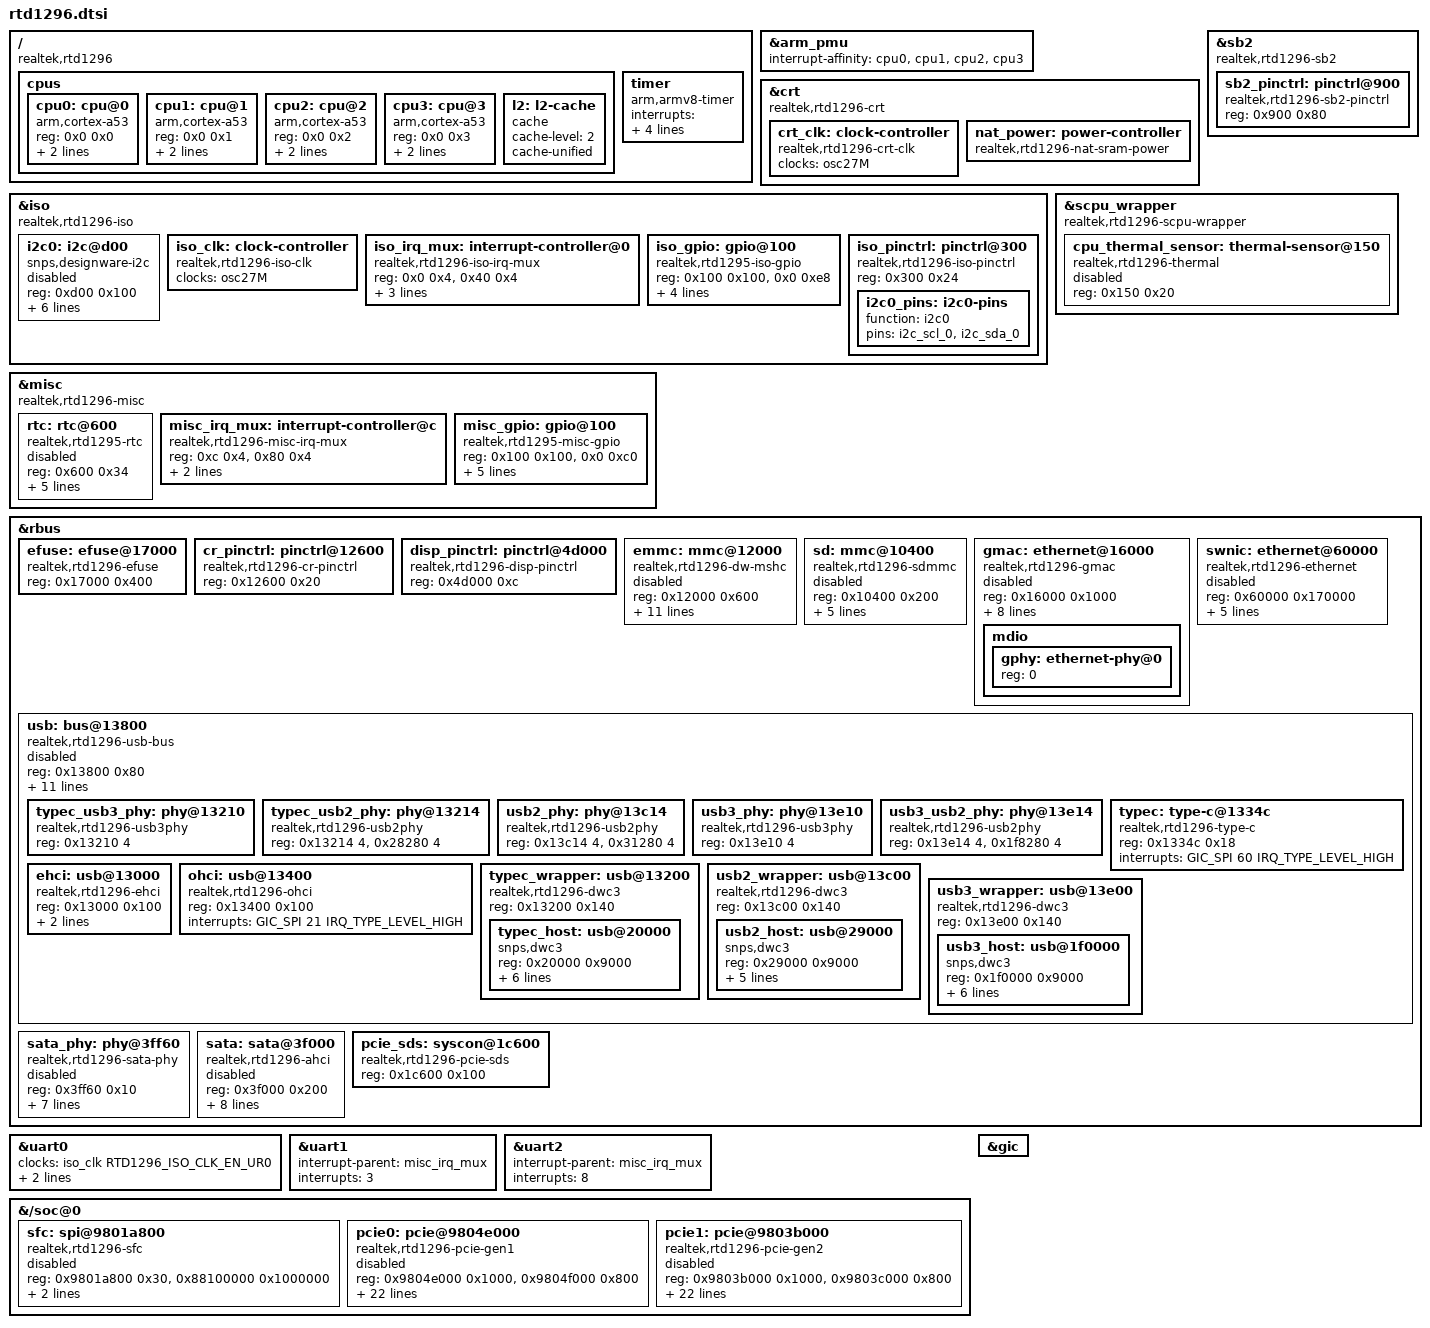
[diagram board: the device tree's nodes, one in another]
// SPDX-License-Identifier: (GPL-2.0-or-later OR BSD-2-Clause)
/*
 * Realtek RTD1296 SoC
 *
 * Copyright (c) 2017-2019 Andreas Färber
 */

#include <dt-bindings/clock/realtek,rtd1296-clk.h>

#include "rtd129x.dtsi"

/ {
	compatible = "realtek,rtd1296";

	cpus {
		#address-cells = <2>;
		#size-cells = <0>;

		cpu0: cpu@0 {
			device_type = "cpu";
			compatible = "arm,cortex-a53";
			reg = <0x0 0x0>;
			next-level-cache = <&l2>;
			clocks = <&crt_clk RTD1296_CRT_CLK_SCPU>;
			#cooling-cells = <2>;
		};

		cpu1: cpu@1 {
			device_type = "cpu";
			compatible = "arm,cortex-a53";
			reg = <0x0 0x1>;
			next-level-cache = <&l2>;
			clocks = <&crt_clk RTD1296_CRT_CLK_SCPU>;
			#cooling-cells = <2>;
		};

		cpu2: cpu@2 {
			device_type = "cpu";
			compatible = "arm,cortex-a53";
			reg = <0x0 0x2>;
			next-level-cache = <&l2>;
			clocks = <&crt_clk RTD1296_CRT_CLK_SCPU>;
			#cooling-cells = <2>;
		};

		cpu3: cpu@3 {
			device_type = "cpu";
			compatible = "arm,cortex-a53";
			reg = <0x0 0x3>;
			next-level-cache = <&l2>;
			clocks = <&crt_clk RTD1296_CRT_CLK_SCPU>;
			#cooling-cells = <2>;
		};

		l2: l2-cache {
			compatible = "cache";
			cache-level = <2>;
			cache-unified;
		};
	};

	timer {
		compatible = "arm,armv8-timer";
		interrupts = <GIC_PPI 13
			(GIC_CPU_MASK_SIMPLE(4) | IRQ_TYPE_LEVEL_LOW)>,
			     <GIC_PPI 14
			(GIC_CPU_MASK_SIMPLE(4) | IRQ_TYPE_LEVEL_LOW)>,
			     <GIC_PPI 11
			(GIC_CPU_MASK_SIMPLE(4) | IRQ_TYPE_LEVEL_LOW)>,
			     <GIC_PPI 10
			(GIC_CPU_MASK_SIMPLE(4) | IRQ_TYPE_LEVEL_LOW)>;
	};
};

&arm_pmu {
	interrupt-affinity = <&cpu0>, <&cpu1>, <&cpu2>, <&cpu3>;
};

&crt {
	compatible = "realtek,rtd1296-crt", "syscon", "simple-mfd";

	crt_clk: clock-controller {
		compatible = "realtek,rtd1296-crt-clk";
		clocks = <&osc27M>;
		#clock-cells = <1>;
	};

	nat_power: power-controller {
		compatible = "realtek,rtd1296-nat-sram-power";
		#power-domain-cells = <0>;
	};
};

&iso {
	compatible = "realtek,rtd1296-iso", "syscon", "simple-mfd";

	i2c0: i2c@d00 {
		compatible = "snps,designware-i2c";
		reg = <0xd00 0x100>;
		interrupt-parent = <&iso_irq_mux>;
		interrupts = <8>;
		clocks = <&iso_clk RTD1296_ISO_CLK_EN_I2C0>;
		resets = <&iso_reset RTD1295_ISO_RSTN_I2C_0>;
		clock-frequency = <100000>;
		#address-cells = <1>;
		#size-cells = <0>;
		pinctrl-names = "default";
		pinctrl-0 = <&i2c0_pins>;
		status = "disabled";
	};

	iso_clk: clock-controller {
		compatible = "realtek,rtd1296-iso-clk";
		clocks = <&osc27M>;
		#clock-cells = <1>;
	};

	iso_irq_mux: interrupt-controller@0 {
		compatible = "realtek,rtd1296-iso-irq-mux";
		reg = <0x0 0x4>, <0x40 0x4>;
		interrupts = <GIC_SPI 41 IRQ_TYPE_LEVEL_HIGH>,
			     <GIC_SPI 39 IRQ_TYPE_LEVEL_HIGH>;
		interrupt-names = "peripherals", "rtc-alarm";
		interrupt-controller;
		#interrupt-cells = <1>;
	};

	iso_gpio: gpio@100 {
		compatible = "realtek,rtd1295-iso-gpio";
		reg = <0x100 0x100>,
		      <0x0 0xe8>;
		interrupt-parent = <&iso_irq_mux>;
		interrupts = <19>, <20>;
		gpio-ranges = <&iso_pinctrl 0 0 35>;
		gpio-controller;
		#gpio-cells = <2>;
	};

	iso_pinctrl: pinctrl@300 {
		compatible = "realtek,rtd1296-iso-pinctrl";
		reg = <0x300 0x24>;

		i2c0_pins: i2c0-pins {
			function = "i2c0";
			pins = "i2c_scl_0", "i2c_sda_0";
		};
	};
};

&misc {
	compatible = "realtek,rtd1296-misc", "syscon", "simple-mfd";

	rtc: rtc@600 {
		compatible = "realtek,rtd1295-rtc";
		reg = <0x600 0x34>;
		clocks = <&crt_clk RTD1296_CRT_CLK_EN_RTC>;
		interrupt-parent = <&iso_irq_mux>;
		interrupts = <13>;
		realtek,iso-syscon = <&iso>;
		wakeup-source;
		status = "disabled";
	};

	misc_irq_mux: interrupt-controller@c {
		compatible = "realtek,rtd1296-misc-irq-mux";
		reg = <0xc 0x4>, <0x80 0x4>;
		interrupts = <GIC_SPI 40 IRQ_TYPE_LEVEL_HIGH>;
		interrupt-controller;
		#interrupt-cells = <1>;
	};

	misc_gpio: gpio@100 {
		compatible = "realtek,rtd1295-misc-gpio";
		reg = <0x100 0x100>,
		      <0x0 0xc0>;
		interrupt-parent = <&misc_irq_mux>;
		interrupts = <19>, <20>;
		gpio-ranges = <&sb2_pinctrl 0 0 54>,
			      <&disp_pinctrl 54 0 10>,
			      <&cr_pinctrl 64 0 37>;
		gpio-controller;
		#gpio-cells = <2>;
	};
};

&sb2 {
	compatible = "realtek,rtd1296-sb2", "syscon", "simple-mfd";

	sb2_pinctrl: pinctrl@900 {
		compatible = "realtek,rtd1296-sb2-pinctrl";
		reg = <0x900 0x80>;
	};
};

&scpu_wrapper {
	compatible = "realtek,rtd1296-scpu-wrapper", "syscon", "simple-mfd";

	cpu_thermal_sensor: thermal-sensor@150 {
		compatible = "realtek,rtd1296-thermal";
		reg = <0x150 0x20>;
		#thermal-sensor-cells = <0>;
		status = "disabled";
	};
};

&rbus {
	efuse: efuse@17000 {
		compatible = "realtek,rtd1296-efuse";
		reg = <0x17000 0x400>;
	};

	cr_pinctrl: pinctrl@12600 {
		compatible = "realtek,rtd1296-cr-pinctrl";
		reg = <0x12600 0x20>;
	};

	disp_pinctrl: pinctrl@4d000 {
		compatible = "realtek,rtd1296-disp-pinctrl";
		reg = <0x4d000 0xc>;
	};

	emmc: mmc@12000 {
		compatible = "realtek,rtd1296-dw-mshc";
		reg = <0x12000 0x600>;
		interrupts = <GIC_SPI 42 IRQ_TYPE_LEVEL_HIGH>;
		clocks = <&crt_clk RTD1296_CRT_CLK_EN_EMMC_IP>,
			 <&crt_clk RTD1296_CRT_CLK_EN_CR>,
			 <&crt_clk RTD1296_CRT_CLK_EN_EMMC>,
			 <&crt_clk RTD1296_CRT_CLK_EMMC_DRIVE>,
			 <&crt_clk RTD1296_CRT_CLK_EMMC_SAMPLE>;
		clock-names = "ciu", "biu", "card", "ciu-drive", "ciu-sample";
		resets = <&reset2 RTD1295_RSTN_EMMC>, <&reset2 RTD1295_RSTN_CR>;
		reset-names = "reset", "cr";
		non-removable;
		no-sd;
		no-sdio;
		status = "disabled";
	};

	sd: mmc@10400 {
		compatible = "realtek,rtd1296-sdmmc";
		reg = <0x10400 0x200>;
		interrupts = <GIC_SPI 44 IRQ_TYPE_LEVEL_HIGH>;
		clocks = <&crt_clk RTD1296_CRT_CLK_EN_CR>,
			 <&crt_clk RTD1296_CRT_CLK_EN_SD_IP>;
		clock-names = "biu", "ciu";
		resets = <&reset2 RTD1295_RSTN_CR>;
		realtek,sb2 = <&sb2>;
		status = "disabled";
	};

	gmac: ethernet@16000 {
		compatible = "realtek,rtd1296-gmac";
		reg = <0x16000 0x1000>;
		interrupts = <GIC_SPI 22 IRQ_TYPE_LEVEL_HIGH>;
		clocks = <&iso_clk RTD1296_ISO_CLK_EN_ETN_250M>,
			 <&iso_clk RTD1296_ISO_CLK_EN_ETN_SYS>;
		clock-names = "mac", "bus";
		resets = <&iso_reset RTD1295_ISO_RSTN_GMAC>,
			 <&iso_reset RTD1295_ISO_RSTN_GPHY>;
		reset-names = "gmac", "gphy";
		realtek,iso = <&iso>;
		phy-mode = "internal";
		phy-handle = <&gphy>;
		status = "disabled";

		mdio {
			#address-cells = <1>;
			#size-cells = <0>;

			gphy: ethernet-phy@0 {
				reg = <0>;
			};
		};
	};

	swnic: ethernet@60000 {
		compatible = "realtek,rtd1296-ethernet";
		reg = <0x60000 0x170000>;
		interrupts = <GIC_SPI 24 IRQ_TYPE_LEVEL_HIGH>;
		clocks = <&crt_clk RTD1296_CRT_CLK_EN_NAT>,
			 <&crt_clk RTD1296_CRT_PLL_DDSB>;
		clock-names = "bus", "core";
		resets = <&reset1 RTD1295_RSTN_NAT>;
		power-domains = <&nat_power>;
		status = "disabled";
	};

	usb: bus@13800 {
		compatible = "realtek,rtd1296-usb-bus";
		reg = <0x13800 0x80>;
		#address-cells = <1>;
		#size-cells = <1>;
		ranges;
		clocks = <&crt_clk RTD1296_CRT_CLK_EN_USB>;
		resets = <&reset2 RTD1295_RSTN_SDS_PHY>,
			 <&reset1 RTD1295_RSTN_USB_PHY0>,
			 <&reset1 RTD1295_RSTN_USB_PHY1>,
			 <&reset2 RTD1295_RSTN_USB_PHY2>,
			 <&reset1 RTD1295_RSTN_USB3_PHY0_POW>,
			 <&reset2 RTD1295_RSTN_USB_PHY3>,
			 <&reset2 RTD1295_RSTN_USB3_PHY1_POW>,
			 <&reset1 RTD1295_RSTN_USB>,
			 <&reset1 RTD1295_RSTN_USB3_P0_MDIO>,
			 <&reset2 RTD1295_RSTN_USB3_P1_MDIO>;
		reset-names = "serdes", "usb2-0", "usb2-1", "usb2-2", "usb3-0",
			      "usb2-3", "usb3-1", "controller", "mdio0", "mdio1";
		status = "disabled";

		typec_usb3_phy: phy@13210 {
			compatible = "realtek,rtd1296-usb3phy";
			reg = <0x13210 4>;
			#phy-cells = <0>;
		};

		typec_usb2_phy: phy@13214 {
			compatible = "realtek,rtd1296-usb2phy";
			reg = <0x13214 4>, <0x28280 4>;
			#phy-cells = <0>;
		};

		usb2_phy: phy@13c14 {
			compatible = "realtek,rtd1296-usb2phy";
			reg = <0x13c14 4>, <0x31280 4>;
			#phy-cells = <0>;
		};

		usb3_phy: phy@13e10 {
			compatible = "realtek,rtd1296-usb3phy";
			reg = <0x13e10 4>;
			#phy-cells = <0>;
		};

		usb3_usb2_phy: phy@13e14 {
			compatible = "realtek,rtd1296-usb2phy";
			reg = <0x13e14 4>, <0x1f8280 4>;
			#phy-cells = <0>;
		};

		typec: type-c@1334c {
			compatible = "realtek,rtd1296-type-c";
			reg = <0x1334c 0x18>;
			interrupts = <GIC_SPI 60 IRQ_TYPE_LEVEL_HIGH>;
		};

		ehci: usb@13000 {
			compatible = "realtek,rtd1296-ehci", "generic-ehci";
			reg = <0x13000 0x100>;
			interrupts = <GIC_SPI 21 IRQ_TYPE_LEVEL_HIGH>;
			companion = <&ohci>;
		};

		ohci: usb@13400 {
			compatible = "realtek,rtd1296-ohci";
			reg = <0x13400 0x100>;
			interrupts = <GIC_SPI 21 IRQ_TYPE_LEVEL_HIGH>;
		};

		typec_wrapper: usb@13200 {
			compatible = "realtek,rtd1296-dwc3", "realtek,rtd-dwc3";
			reg = <0x13200 0x140>;
			#address-cells = <1>;
			#size-cells = <1>;
			ranges;

			typec_host: usb@20000 {
				compatible = "snps,dwc3";
				reg = <0x20000 0x9000>;
				interrupts = <GIC_SPI 21 IRQ_TYPE_LEVEL_HIGH>;
				phys = <&typec_usb2_phy>, <&typec_usb3_phy>;
				phy-names = "usb2-phy", "usb3-phy";
				dr_mode = "host";
				maximum-speed = "super-speed";
				snps,dis_u2_susphy_quirk;
				snps,dis_u3_susphy_quirk;
			};
		};

		usb2_wrapper: usb@13c00 {
			compatible = "realtek,rtd1296-dwc3", "realtek,rtd-dwc3";
			reg = <0x13c00 0x140>;
			#address-cells = <1>;
			#size-cells = <1>;
			ranges;

			usb2_host: usb@29000 {
				compatible = "snps,dwc3";
				reg = <0x29000 0x9000>;
				interrupts = <GIC_SPI 21 IRQ_TYPE_LEVEL_HIGH>;
				phys = <&usb2_phy>;
				phy-names = "usb2-phy";
				dr_mode = "host";
				maximum-speed = "high-speed";
				snps,dis_u2_susphy_quirk;
			};
		};

		usb3_wrapper: usb@13e00 {
			compatible = "realtek,rtd1296-dwc3", "realtek,rtd-dwc3";
			reg = <0x13e00 0x140>;
			#address-cells = <1>;
			#size-cells = <1>;
			ranges;

			usb3_host: usb@1f0000 {
				compatible = "snps,dwc3";
				reg = <0x1f0000 0x9000>;
				interrupts = <GIC_SPI 21 IRQ_TYPE_LEVEL_HIGH>;
				phys = <&usb3_usb2_phy>, <&usb3_phy>;
				phy-names = "usb2-phy", "usb3-phy";
				dr_mode = "host";
				maximum-speed = "super-speed";
				snps,dis_u2_susphy_quirk;
				snps,dis_u3_susphy_quirk;
			};
		};
	};

	sata_phy: phy@3ff60 {
		compatible = "realtek,rtd1296-sata-phy";
		reg = <0x3ff60 0x10>;
		#phy-cells = <1>;
		clocks = <&crt_clk RTD1296_CRT_CLK_EN_SATA_ALIVE0>,
			 <&crt_clk RTD1296_CRT_CLK_EN_SATA_ALIVE1>;
		clock-names = "port0", "port1";
		resets = <&reset2 RTD1295_RSTN_SDS_PHY>,
			 <&reset1 RTD1295_RSTN_SATA_PHY_POW_0>,
			 <&reset4 RTD1295_RSTN_SATA_PHY_POW_1>;
		reset-names = "serdes", "port0", "port1";
		realtek,sb2 = <&sb2>;
		status = "disabled";
	};

	sata: sata@3f000 {
		compatible = "realtek,rtd1296-ahci", "generic-ahci";
		reg = <0x3f000 0x200>;
		interrupts = <GIC_SPI 28 IRQ_TYPE_LEVEL_HIGH>;
		clocks = <&crt_clk RTD1296_CRT_CLK_EN_SATA0>,
			 <&crt_clk RTD1296_CRT_CLK_EN_SATA1>;
		resets = <&reset1 RTD1295_RSTN_SATA_0>,
			 <&reset1 RTD1295_RSTN_SATA_PHY_0>,
			 <&reset4 RTD1295_RSTN_SATA_1>,
			 <&reset4 RTD1295_RSTN_SATA_PHY_1>;
		ports-implemented = <3>;
		#address-cells = <1>;
		#size-cells = <0>;
		status = "disabled";
	};

	pcie_sds: syscon@1c600 {
		compatible = "realtek,rtd1296-pcie-sds", "syscon";
		reg = <0x1c600 0x100>;
	};
};

&uart0 {
	/delete-property/ clock-frequency;
	clocks = <&iso_clk RTD1296_ISO_CLK_EN_UR0>;
	interrupt-parent = <&iso_irq_mux>;
	interrupts = <2>;
};

&uart1 {
	interrupt-parent = <&misc_irq_mux>;
	interrupts = <3>;
};

&uart2 {
	interrupt-parent = <&misc_irq_mux>;
	interrupts = <8>;
};

&{/soc@0} {
	sfc: spi@9801a800 {
		compatible = "realtek,rtd1296-sfc";
		reg = <0x9801a800 0x30>, <0x88100000 0x1000000>;
		reg-names = "ctrl", "flash";
		clocks = <&crt_clk RTD1296_CRT_CLK_SYS_SB2>;
		realtek,sb2 = <&sb2>;
		#address-cells = <1>;
		#size-cells = <0>;
		status = "disabled";
	};

	pcie0: pcie@9804e000 {
		compatible = "realtek,rtd1296-pcie-gen1";
		reg = <0x9804e000 0x1000>, <0x9804f000 0x800>;
		device_type = "pci";
		#address-cells = <3>;
		#size-cells = <2>;
		#interrupt-cells = <1>;
		linux,pci-domain = <0>;
		bus-range = <0 0>;
		ranges = <0x02000000 0 0xc0000000 0x9804f000 0 0x800>;
		dma-ranges = <0x02000000 0 0 0 0 0x80000000>;
		clocks = <&crt_clk RTD1296_CRT_CLK_EN_PCIE0>;
		resets = <&reset2 RTD1295_RSTN_PCIE0_STITCH>,
			 <&reset2 RTD1295_RSTN_PCIE0>,
			 <&reset2 RTD1295_RSTN_PCIE0_CORE>,
			 <&reset2 RTD1295_RSTN_PCIE0_POWER>,
			 <&reset2 RTD1295_RSTN_PCIE0_NONSTICH>,
			 <&reset2 RTD1295_RSTN_PCIE0_PHY>,
			 <&reset4 RTD1295_RSTN_PCIE0_PHY_MDIO>,
			 <&reset2 RTD1295_RSTN_SDS_PHY>;
		reset-names = "stitch", "main", "core", "power", "non-stitch",
			      "phy", "mdio", "serdes";
		realtek,sds = <&pcie_sds>;
		realtek,sb2 = <&sb2>;
		interrupt-map-mask = <0 0 0 7>;
		interrupt-map = <0 0 0 1 &gic GIC_SPI 61 IRQ_TYPE_LEVEL_HIGH>,
				<0 0 0 2 &gic GIC_SPI 61 IRQ_TYPE_LEVEL_HIGH>,
				<0 0 0 3 &gic GIC_SPI 61 IRQ_TYPE_LEVEL_HIGH>,
				<0 0 0 4 &gic GIC_SPI 61 IRQ_TYPE_LEVEL_HIGH>;
		status = "disabled";
		interrupts = <GIC_SPI 61 IRQ_TYPE_LEVEL_HIGH>;
		interrupt-names = "msi";
		msi-controller;
		#msi-cells = <0>;
	};

	pcie1: pcie@9803b000 {
		compatible = "realtek,rtd1296-pcie-gen2";
		reg = <0x9803b000 0x1000>, <0x9803c000 0x800>;
		device_type = "pci";
		#address-cells = <3>;
		#size-cells = <2>;
		#interrupt-cells = <1>;
		linux,pci-domain = <1>;
		bus-range = <0 0>;
		ranges = <0x02000000 0 0xc1000000 0x9803c000 0 0x800>;
		dma-ranges = <0x02000000 0 0 0 0 0x80000000>;
		clocks = <&crt_clk RTD1296_CRT_CLK_EN_PCIE1>;
		resets = <&reset2 RTD1295_RSTN_PCIE1_STITCH>,
			 <&reset2 RTD1295_RSTN_PCIE1>,
			 <&reset2 RTD1295_RSTN_PCIE1_CORE>,
			 <&reset2 RTD1295_RSTN_PCIE1_POWER>,
			 <&reset2 RTD1295_RSTN_PCIE1_NONSTICH>,
			 <&reset2 RTD1295_RSTN_PCIE1_PHY>,
			 <&reset4 RTD1295_RSTN_PCIE1_PHY_MDIO>,
			 <&reset2 RTD1295_RSTN_SDS_PHY>;
		reset-names = "stitch", "main", "core", "power", "non-stitch",
			      "phy", "mdio", "serdes";
		realtek,sds = <&pcie_sds>;
		realtek,sb2 = <&sb2>;
		interrupt-map-mask = <0 0 0 7>;
		interrupt-map = <0 0 0 1 &gic GIC_SPI 62 IRQ_TYPE_LEVEL_HIGH>,
				<0 0 0 2 &gic GIC_SPI 62 IRQ_TYPE_LEVEL_HIGH>,
				<0 0 0 3 &gic GIC_SPI 62 IRQ_TYPE_LEVEL_HIGH>,
				<0 0 0 4 &gic GIC_SPI 62 IRQ_TYPE_LEVEL_HIGH>;
		status = "disabled";
		interrupts = <GIC_SPI 62 IRQ_TYPE_LEVEL_HIGH>;
		interrupt-names = "msi";
		msi-controller;
		#msi-cells = <0>;
	};
};

&gic {
	#address-cells = <0>;
};
